# LPC8N04 register map
Vendor: nxp.com; File version: 1.0
CPU: CM0PLUS r0p0, little endian, no MPU, no FPU, VTOR, 2 interrupt priority bits
Registers are 32-bit, read-write, reset 0x0 unless marked. A register's access mark holds for its fields unless they carry their own. Offsets are from the block's base; [hi:lo] are bit positions; {n}, {i} and the like mark numbered series.

## CT16B0 — 16-bit counter/timer 0
Base 0x4000C000
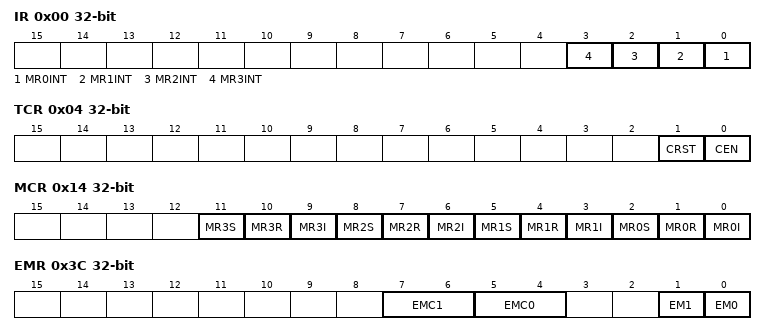
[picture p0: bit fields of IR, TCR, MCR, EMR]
0x00 IR — Interrupt register. The IR can be written to clear interrupts, and can be read to identify which of the five possible interrupt sources are pending.
  [n] MR{n}INT (n=0..3) — Interrupt flag for match channel {n}
0x04 TCR — Timer control register. The TCR is used to control the timer counter functions. The TC can be disabled or reset through the TCR
  [1] CRST — Counter Reset. When one, the Timer Counter and the Prescale Counter are synchronously reset on the next positive edge of PCLK. The counters remain reset until TCR[1] is returned to zero.
  [0] CEN — Counter Enable. When one, the Timer Counter and Prescale Counter are enabled for counting. When zero, the counters are disabled.
0x08 TC — Timer Counter (TC). The 16-bit TC is incremented every PR+1 cycles of PCLK. The TC is controlled through the TCR.
  [15:0] TC — Timer counter value
0x0C PR — Prescale register. When the Prescale Counter (below) is equal to this value, the next clock increments the TC and clears the PC.
  [15:0] PR — Prescale max value
0x10 PC — Prescale Counter (PC). The 16-bit PC is a counter which is incremented to the value stored in PR. When the value in PR is reached, the TC is incremented and the PC is cleared. The PC is observable and controllable through the bus interface.
  [15:0] PC — Prescale counter value
0x14 MCR — Match Control Register (MCR). The MCR is used to control if an interrupt is generated and if the TC is reset when a Match occurs.
  [all] fields
    0=DISABLED; 1=ENABLED
  [3n+2] MR{n}S (n=0..3) — Stop on MR{n}: the TC and PC will be stopped and TCR[0] will be set to 0 if MR{n} matches the TC.
  [10] MR3R — Reset on MR3: the TC will be reset if MR3 matches it
  [3n] MR{n}I (n=0..3) — Interrupt on MR{n}: an interrupt is generated when MR{n} matches the value in the TC
  [7] MR2R — Reset on MR0: the TC will be reset if MR2 matches it
  [4] MR1R — Reset on MR1: the TC will be reset if MR1 matches it
  [1] MR0R — Reset on MR0: the TC will be reset if MR0 matches it
0x18 MR0 — Match Register 0 (MR0). MR0 can be enabled through the MCR to reset the TC, stop both the TC and PC, and/or generate an interrupt every time MR0 matches the TC.
  [15:0] MATCH — Timer counter match value
{0x18+4i} MR{i} (i=1..3) — Match Register {i} (MR1). See MR0 description.
  [15:0] MATCH — Timer counter match value
0x3C EMR — External Match Register (EMR). The EMR controls the match function and the external match pins CT16B_MAT[1:0].
  [7:6] EMC1 — External match control 1
    0=DO_NOTHING; 1=CLEAR (Clear the corresponding External Match bit/output to 0 (CT16B_MAT1 pin is LOW if pinned out).); 2=SET (Set the corresponding External Match bit/output to 1 (CT16B_MAT1 pin is HIGH if pinned out).); 3=TOGGLE (Toggle the corresponding External Match bit/output.)
  [5:4] EMC0 — External match control 0
    0=DO_NOTHING; 1=CLEAR (Clear the corresponding External Match bit/output to 0 (CT16B_MAT0 pin is LOW if pinned out).); 2=SET (Set the corresponding External Match bit/output to 1 (CT16B_MAT0 pin is HIGH if pinned out).); 3=TOGGLE (Toggle the corresponding External Match bit/output.)
  [1] EM1 — External Match 1. This bit reflects the state of output CT16B_MAT1, whether or not this output is connected to its pin. When a match occurs between the TC and MR0, this bit can either toggle, go LOW, go HIGH, or do nothing. Bits EMR[7:6] control the functionality of this output. This bit is driven to the CT16B_MAT1 pin if the match function is selected in the IOCON registers (0 = LOW, 1 = HIGH). Only valid when the timer is enabled.
  [0] EM0 — External Match 0. This bit reflects the state of output CT16B_MAT0, whether or not this output is connected to its pin. When a match occurs between the TC and MR0, this bit can either toggle, go LOW, go HIGH, or do nothing. Bits EMR[5:4] control the functionality of this output. This bit is driven to the CT16B_MAT0 pin if the match function is selected in the IOCON registers (0 = LOW, 1 = HIGH). Only valid when the timer is enabled.
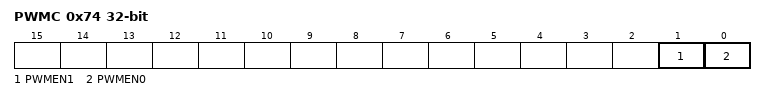
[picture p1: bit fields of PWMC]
0x74 PWMC — PWM Control Register (PWMCON). The PWMCON enables PWM mode for the external match pins CT16B_MAT[1:0].
  [1] PWMEN1 — PWM channel1 enable
    0=DISABLED (CT16B_MAT1 is controlled by EM1); 1=ENABLED (PWM mode is enabled for CT16B_MAT1)
  [0] PWMEN0 — PWM channel0 enable
    0=DISABLED (CT16B_MAT0 is controlled by EM0); 1=ENABLED (PWM mode is enabled for CT16B_MAT0)
